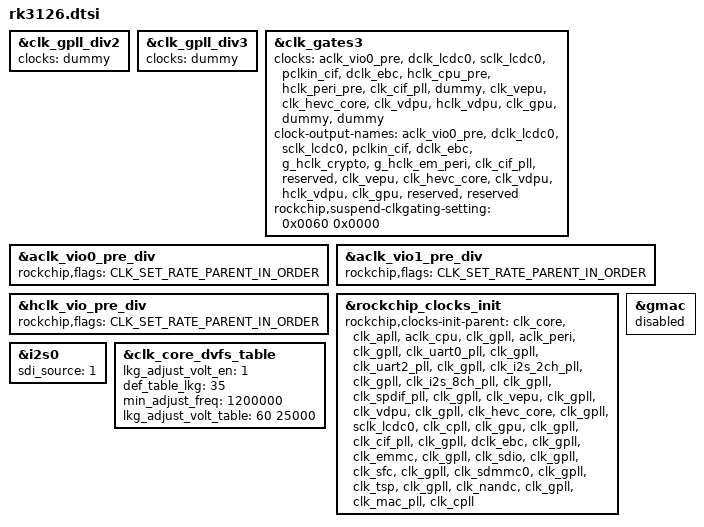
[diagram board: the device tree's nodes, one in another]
#include "rk312x.dtsi"

&clk_gpll_div2 {
	clocks = <&dummy>;
};

&clk_gpll_div3 {
	clocks = <&dummy>;
};

&clk_gates3 {
	clocks =
		<&aclk_vio0_pre>,	<&dclk_lcdc0>,
		<&sclk_lcdc0>,		<&pclkin_cif>,

		<&dclk_ebc>,		<&hclk_cpu_pre>,
		<&hclk_peri_pre>,	<&clk_cif_pll>,

		<&dummy>,		<&clk_vepu>,
		<&clk_hevc_core>,	<&clk_vdpu>,

		<&hclk_vdpu>,		<&clk_gpu>,
		<&dummy>,		<&dummy>;

	clock-output-names =
		"aclk_vio0_pre",	"dclk_lcdc0",
		"sclk_lcdc0",		"pclkin_cif",

		"dclk_ebc",		"g_hclk_crypto",
		"g_hclk_em_peri",	"clk_cif_pll",

		"reserved",		"clk_vepu",
		"clk_hevc_core",	"clk_vdpu",

		"hclk_vdpu",		"clk_gpu",
		"reserved",		"reserved";
	rockchip,suspend-clkgating-setting=<0x0060 0x0000>;
};

&aclk_vio0_pre_div {
	rockchip,flags = <CLK_SET_RATE_PARENT_IN_ORDER>;
};

&aclk_vio1_pre_div {
        rockchip,flags = <CLK_SET_RATE_PARENT_IN_ORDER>;
};

&hclk_vio_pre_div {
        rockchip,flags = <CLK_SET_RATE_PARENT_IN_ORDER>;
};

&rockchip_clocks_init {
	rockchip,clocks-init-parent =
		<&clk_core &clk_apll>, <&aclk_cpu &clk_gpll>,
		<&aclk_peri &clk_gpll>, <&clk_uart0_pll &clk_gpll>,
		<&clk_uart2_pll &clk_gpll>, <&clk_i2s_2ch_pll &clk_gpll>,
		<&clk_i2s_8ch_pll &clk_gpll>, <&clk_spdif_pll &clk_gpll>,
		<&clk_vepu &clk_gpll>, <&clk_vdpu &clk_gpll>,
		<&clk_hevc_core &clk_gpll>,
		<&sclk_lcdc0 &clk_cpll>, <&clk_gpu &clk_gpll>,
		<&clk_cif_pll &clk_gpll>, <&dclk_ebc &clk_gpll>,
		<&clk_emmc &clk_gpll>, <&clk_sdio &clk_gpll>,
		<&clk_sfc &clk_gpll>, <&clk_sdmmc0 &clk_gpll>,
		<&clk_tsp &clk_gpll>, <&clk_nandc &clk_gpll>,
		<&clk_mac_pll &clk_cpll>;
};

&gmac {
	status = "disabled";
};

&i2s0 {
	/* sdi: 0: from io, 1: from acodec */
	sdi_source = <1>;
	status = "okay";
};

&clk_core_dvfs_table {
	lkg_adjust_volt_en = <1>;
	def_table_lkg = <35>;
	min_adjust_freq = <1200000>;
	lkg_adjust_volt_table = <
		/*lkg(mA)  volt(uV)*/
		60         25000
		>;
};
